# SF32LB57x register map
File version: 1.0
CPU: CM33 r0p1, little endian, MPU, FPU, 3 interrupt priority bits
Registers are 32-bit, read-write, reset 0x0 unless marked. A register's access mark holds for its fields unless they carry their own. Offsets are from the block's base; [hi:lo] are bit positions; {n}, {i} and the like mark numbered series.

## CRC1
Base 0x50048000
Same registers: CRC2 0x40085000
0x00 DR reset 0xFFFFFFFF — Data register
  [31:0] DR — Data register bits. This register is used to write new data to the CRC calculator. It holds the previous CRC calculation result when it is read. If the data size is less than 32 bits, the least significant bits are used to write/read the correct value.
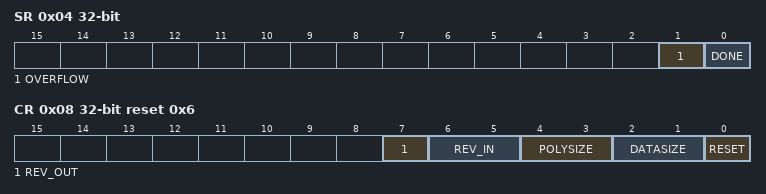
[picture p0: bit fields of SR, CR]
0x04 SR — Status register
  [1] OVERFLOW — Overflow when new data arrive while last calculation not done yet
  [0] DONE — Done flag. When DR written, done flag will be cleared automatically. The flag will assert after CRC operation of current DR finished.
0x08 CR reset 0x6 — Control register
  [7] REV_OUT — Reverse output data This bit controls the reversal of the bit order of the output data. 0: Bit order not affected 1: Bit-reversed output format
  [6:5] REV_IN — Reverse input data These bits control the reversal of the bit order of the input data 00: Bit order not affected 01: Bit reversal done by byte 10: Bit reversal done by half-word 11: Bit reversal done by word
  [4:3] POLYSIZE — Polynomial size These bits control the size of the polynomial. 00: 32 bit polynomial 01: 16 bit polynomial 10: 8 bit polynomial 11: 7 bit polynomial
  [2:1] DATASIZE — Valid input data size These bits control the valid size of the input data. 00: lower 8-bit 01: lower 16-bit 10: lower 24-bit 11: all 32-bit
  [0] RESET — This bit is set by software to reset the CRC calculation unit and set the data register to the value stored in the CRC_INIT register. This bit can only be set, it is automatically cleared by hardware
0x10 INIT reset 0xFFFFFFFF — Initial CRC value
  [31:0] INIT — Programmable initial CRC value
0x14 POL reset 0x4C11DB7 — CRC polynomial
  [31:0] POL — Programmable polynomial This register is used to write the coefficients of the polynomial to be used for CRC calculation. If the polynomial size is less than 32 bits, the least significant bits have to be used to program the correct value.

## HPSYS_MAILBOX
Base 0x50082000
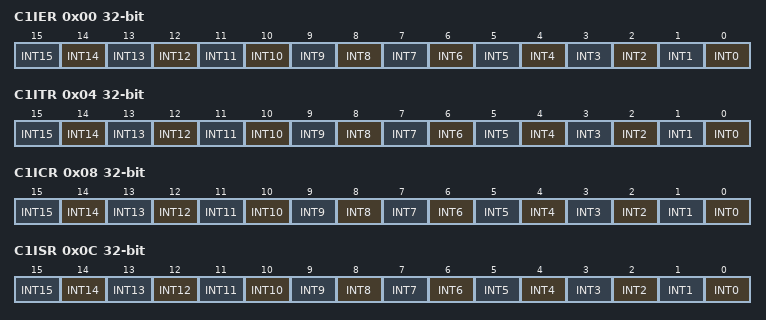
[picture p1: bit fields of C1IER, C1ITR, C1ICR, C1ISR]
0x00 C1IER — Channel 1 INTerrupt Enable Register
  [n] INT{n} (n=0..15)
0x04 C1ITR — Channel 1 INTerrupt Trigger Register
  [n] INT{n} (n=0..15)
0x08 C1ICR — Channel 1 INTerrupt Clear Register
  [n] INT{n} (n=0..15)
0x0C C1ISR — Channel 1 INTerrupt Status Register
  [n] INT{n} (n=0..15)
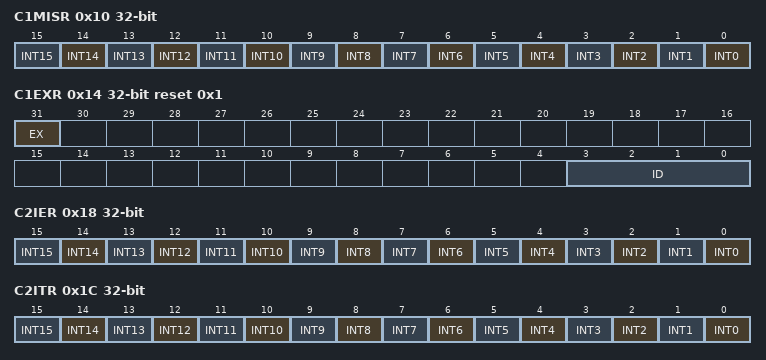
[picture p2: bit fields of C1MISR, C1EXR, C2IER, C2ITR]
0x10 C1MISR — Channel 1 Masked INTerrupt Status Register
  [n] INT{n} (n=0..15)
0x14 C1EXR reset 0x1 — Channel 1 Mutual Exclusive Register
  [31] EX, [3:0] ID
0x18 C2IER — Channel 2 INTerrupt Enable Register
  [n] INT{n} (n=0..15)
0x1C C2ITR — Channel 2 INTerrupt Trigger Register
  [n] INT{n} (n=0..15)
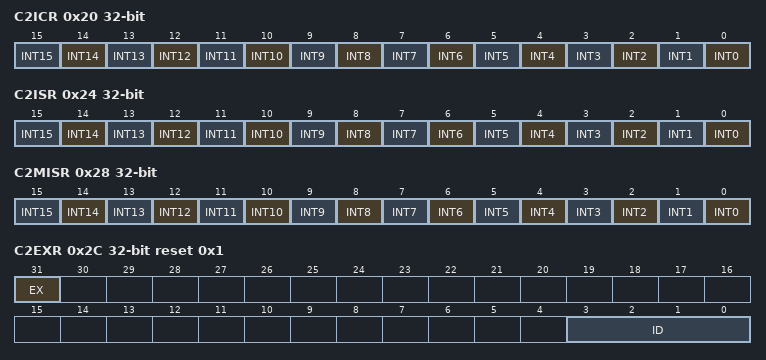
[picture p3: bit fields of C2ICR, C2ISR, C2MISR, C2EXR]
0x20 C2ICR — Channel 2 INTerrupt Clear Register
  [n] INT{n} (n=0..15)
0x24 C2ISR — Channel 2 INTerrupt Status Register
  [n] INT{n} (n=0..15)
0x28 C2MISR — Channel 2 Masked INTerrupt Status Register
  [n] INT{n} (n=0..15)
0x2C C2EXR reset 0x1 — Channel 2 Mutual Exclusive Register
  [31] EX, [3:0] ID
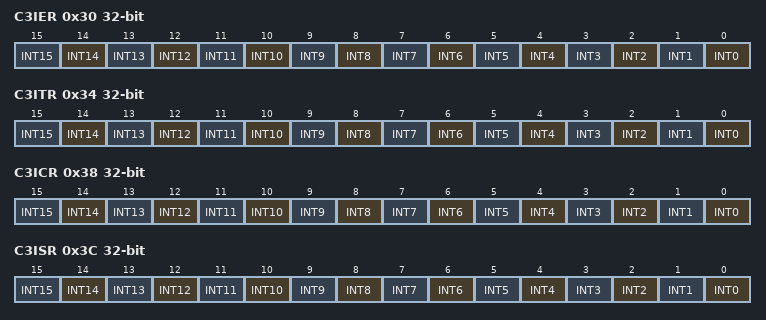
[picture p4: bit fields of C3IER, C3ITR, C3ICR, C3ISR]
0x30 C3IER — Channel 3 INTerrupt Enable Register
  [n] INT{n} (n=0..15)
0x34 C3ITR — Channel 3 INTerrupt Trigger Register
  [n] INT{n} (n=0..15)
0x38 C3ICR — Channel 3 INTerrupt Clear Register
  [n] INT{n} (n=0..15)
0x3C C3ISR — Channel 3 INTerrupt Status Register
  [n] INT{n} (n=0..15)
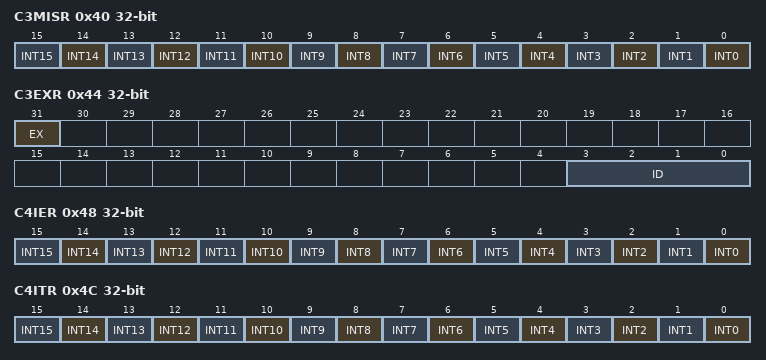
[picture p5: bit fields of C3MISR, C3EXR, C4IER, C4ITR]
0x40 C3MISR — Channel 3 Masked INTerrupt Status Register
  [n] INT{n} (n=0..15)
0x44 C3EXR — Channel 3 Mutual Exclusive Register
  [31] EX, [3:0] ID
0x48 C4IER — Channel 4 INTerrupt Enable Register
  [n] INT{n} (n=0..15)
0x4C C4ITR — Channel 4 INTerrupt Trigger Register
  [n] INT{n} (n=0..15)
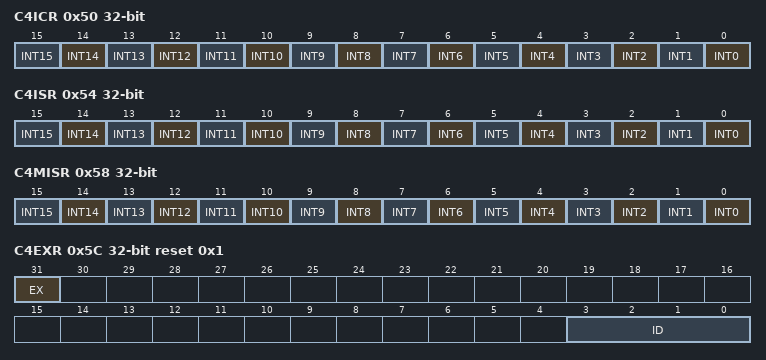
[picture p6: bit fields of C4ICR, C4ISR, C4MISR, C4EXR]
0x50 C4ICR — Channel 4 INTerrupt Clear Register
  [n] INT{n} (n=0..15)
0x54 C4ISR — Channel 4 INTerrupt Status Register
  [n] INT{n} (n=0..15)
0x58 C4MISR — Channel 4 Masked INTerrupt Status Register
  [n] INT{n} (n=0..15)
0x5C C4EXR reset 0x1 — Channel 4 Mutual Exclusive Register
  [31] EX, [3:0] ID

## LPSYS_MAILBOX
Base 0x40002000
Registers as HPSYS_MAILBOX, without C3IER, C3ITR, C3ICR, C3ISR, C3MISR, C3EXR, C4IER, C4ITR, C4ICR, C4ISR, C4MISR, C4EXR.
